# STM32U083 register map
File version: 1.0
CPU: CM0+ r0p1, little endian, MPU, no FPU, 4 interrupt priority bits
Registers are 32-bit, read-write, reset 0x0 unless marked. A register's access mark holds for its fields unless they carry their own. Offsets are from the block's base; [hi:lo] are bit positions.

## LPUART1 — LPUART address block description
Base 0x40008000
Same registers: LPUART2 0x40008400, LPUART3 0x40008C00
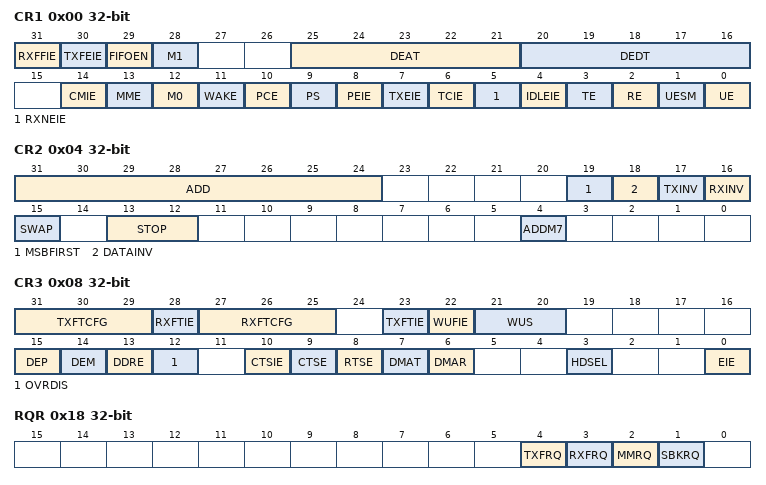
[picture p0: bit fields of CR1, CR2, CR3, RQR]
0x00 CR1 — LPUART control register 1
  [31] RXFFIE — RXFIFO Full interrupt enable This bit is set and cleared by software.
    0=Disabled (Interrupt inhibited); 1=Enabled (USART interrupt generated when RXFF = 1 in the USART_ISR register)
  [30] TXFEIE — TXFIFO empty interrupt enable This bit is set and cleared by software.
    0=Disabled (Interrupt inhibited); 1=Enabled (USART interrupt generated when TXFE = 1 in the USART_ISR register)
  [29] FIFOEN — FIFO mode enable This bit is set and cleared by software.
    0=Disabled (FIFO mode is disabled); 1=Enabled (FIFO mode is enabled)
  [28] M1 — Word length This bit must be used in conjunction with bit 12 (M0) to determine the word length. It is set or cleared by software. M[1:0] = 00: 1 Start bit, 8 Data bits, n Stop bit M[1:0] = 01: 1 Start bit, 9 Data bits, n Stop bit M[1:0] = 10: 1 Start bit, 7 Data bits, n Stop bit This bit can only be written when the LPUART is disabled (UE=0). Note: In 7-bit data length mode, the Smartcard mode, LIN master mode and auto baud rate (0x7F and 0x55 frames detection) are not supported.
    0=M0 (Use M0 to set the data bits); 1=Bit7 (1 start bit, 7 data bits, n stop bits)
  [25:21] DEAT — Driver Enable assertion time This 5-bit value defines the time between the activation of the DE (Driver Enable) signal and the beginning of the start bit. It is expressed in lpuart_ker_ck clock cycles. For more details, refer Section131.5.21: RS232 Hardware flow control and RS485 Driver Enable. This bitfield can only be written when the LPUART is disabled (UE=0).
  [20:16] DEDT — Driver Enable deassertion time This 5-bit value defines the time between the end of the last stop bit, in a transmitted message, and the de-activation of the DE (Driver Enable) signal.It is expressed in lpuart_ker_ck clock cycles. For more details, refer Section132.4.14: RS232 Hardware flow control and RS485 Driver Enable. If the LPUART_TDR register is written during the DEDT time, the new data is transmitted only when the DEDT and DEAT times have both elapsed. This bitfield can only be written when the LPUART is disabled (UE=0).
  [14] CMIE — Character match interrupt enable This bit is set and cleared by software.
    0=Disabled (Interrupt is disabled); 1=Enabled (Interrupt is generated when the CMF bit is set in the ISR register)
  [13] MME — Mute mode enable This bit activates the Mute mode function of the LPUART. When set, the LPUART can switch between the active and Mute modes, as defined by the WAKE bit. It is set and cleared by software.
    0=Disabled (Receiver in active mode permanently); 1=Enabled (Receiver can switch between mute mode and active mode)
  [12] M0 — Word length This bit is used in conjunction with bit 28 (M1) to determine the word length. It is set or cleared by software (refer to bit 28 (M1) description). This bit can only be written when the LPUART is disabled (UE=0).
    0=Bit8 (1 start bit, 8 data bits, n stop bits); 1=Bit9 (1 start bit, 9 data bits, n stop bits)
  [11] WAKE — Receiver wake-up method This bit determines the LPUART wake-up method from Mute mode. It is set or cleared by software. This bitfield can only be written when the LPUART is disabled (UE=0).
    0=Idle line; 1=Address mask
  [10] PCE — Parity control enable This bit selects the hardware parity control (generation and detection). When the parity control is enabled, the computed parity is inserted at the MSB position (9th bit if M=1; 8th bit if M=0) and parity is checked on the received data. This bit is set and cleared by software. Once it is set, PCE is active after the current byte (in reception and in transmission). This bitfield can only be written when the LPUART is disabled (UE=0).
    0=Disabled (Parity control disabled); 1=Enabled (Parity control enabled)
  [9] PS — Parity selection This bit selects the odd or even parity when the parity generation/detection is enabled (PCE bit set). It is set and cleared by software. The parity is selected after the current byte. This bitfield can only be written when the LPUART is disabled (UE=0).
    0=Even parity; 1=Odd (Odd parity)
  [8] PEIE — PE interrupt enable This bit is set and cleared by software.
    0=Disabled (Interrupt is disabled); 1=Enabled (Interrupt is generated whenever PE=1 in the ISR register)
  [7] TXEIE — TXFIFO not full interrupt enable This bit is set and cleared by software.
    0=Disabled (Interrupt is disabled); 1=Enabled (Interrupt is generated whenever TXE=1 in the ISR register)
  [6] TCIE — Transmission complete interrupt enable This bit is set and cleared by software.
    0=Disabled (Interrupt is disabled); 1=Enabled (Interrupt is generated whenever TC=1 in the ISR register)
  [5] RXNEIE — RXFIFO not empty interrupt enable This bit is set and cleared by software.
    0=Disabled (Interrupt is disabled); 1=Enabled (Interrupt is generated whenever ORE=1 or RXNE=1 in the ISR register)
  [4] IDLEIE — IDLE interrupt enable This bit is set and cleared by software.
    0=Disabled (Interrupt is disabled); 1=Enabled (Interrupt is generated whenever IDLE=1 in the ISR register)
  [3] TE — Transmitter enable This bit enables the transmitter. It is set and cleared by software. Note: During transmission, a low pulse on the TE bit (0 followed by 1) sends a preamble (idle line) after the current word, except in Smartcard mode. In order to generate an idle character, the TE must not be immediately written to 1. To ensure the required duration, the software can poll the TEACK bit in the LPUART_ISR register. Note: In Smartcard mode, when TE is set, there is a 1 bit-time delay before the transmission starts.
    0=Disabled (Transmitter is disabled); 1=Enabled (Transmitter is enabled)
  [2] RE — Receiver enable This bit enables the receiver. It is set and cleared by software.
    0=Disabled (Receiver is disabled); 1=Enabled (Receiver is enabled)
  [1] UESM — LPUART enable in low-power mode When this bit is cleared, the LPUART cannot wake up the MCU from low-power mode. When this bit is set, the LPUART can wake up the MCU from low-power mode. This bit is set and cleared by software. Note: It is recommended to set the UESM bit just before entering low-power mode, and clear it when exiting low-power mode.
    0=Disabled (USART not able to wake up the MCU from Stop mode); 1=Enabled (USART able to wake up the MCU from Stop mode)
  [0] UE — LPUART enable When this bit is cleared, the LPUART prescalers and outputs are stopped immediately, and current operations are discarded. The configuration of the LPUART is kept, but all the status flags, in the LPUART_ISR are reset. This bit is set and cleared by software. Note: To enter low-power mode without generating errors on the line, the TE bit must be reset before and the software must wait for the TC bit in the LPUART_ISR to be set before resetting the UE bit. Note: The DMA requests are also reset when UE = 0 so the DMA channel must be disabled before resetting the UE bit.
    0=Disabled (UART is disabled); 1=Enabled (UART is enabled)
0x04 CR2 — LPUART control register 2
  [31:24] ADD — Address of the LPUART node These bits give the address of the LPUART node in Mute mode or a character code to be recognized in low-power or Run mode: In Mute mode: they are used in multiprocessor communication to wake up from Mute mode with 4-bit/7-bit address mark detection. The MSB of the character sent by the transmitter should be equal to 1. In 4-bit address mark detection, only ADD[3:0] bits are used. In low-power mode: they are used for wake up from low-power mode on character match. When WUS[1:0] is programmed to 0b00 (WUF active on address match), the wake-up from low-power mode is performed when the received character corresponds to the character programmed through ADD[6:0] or ADD[3:0] bitfield (depending on ADDM7 bit), and WUF interrupt is enabled by setting WUFIE bit. The MSB of the character sent by transmitter should be equal to 1. In Run mode with Mute mode inactive (for example, end-of-block detection in ModBus protocol): the whole received character (8 bits) is compared to ADD[7:0] value and CMF flag is set on match. An interrupt is generated if the CMIE bit is set. These bits can only be written when the reception is disabled (RE1=10) or when the USART is disabled (UE1=10).
  [19] MSBFIRST — Most significant bit first This bit is set and cleared by software. This bitfield can only be written when the LPUART is disabled (UE=0).
    0=LSB (data is transmitted/received with data bit 0 first, following the start bit); 1=MSB (data is transmitted/received with MSB (bit 7/8/9) first, following the start bit)
  [18] DATAINV — Binary data inversion This bit is set and cleared by software. This bitfield can only be written when the LPUART is disabled (UE=0).
    0=Positive (Logical data from the data register are send/received in positive/direct logic); 1=Negative (Logical data from the data register are send/received in negative/inverse logic)
  [17] TXINV — TX pin active level inversion This bit is set and cleared by software. This enables the use of an external inverter on the TX line. This bitfield can only be written when the LPUART is disabled (UE=0).
    0=Standard (TX pin signal works using the standard logic levels); 1=Inverted (TX pin signal values are inverted)
  [16] RXINV — RX pin active level inversion This bit is set and cleared by software. This enables the use of an external inverter on the RX line. This bitfield can only be written when the LPUART is disabled (UE=0).
    0=Standard (RX pin signal works using the standard logic levels); 1=Inverted (RX pin signal values are inverted)
  [15] SWAP — Swap TX/RX pins This bit is set and cleared by software. This bitfield can only be written when the LPUART is disabled (UE=0).
    0=Standard (TX/RX pins are used as defined in standard pinout); 1=Swapped (The TX and RX pins functions are swapped)
  [13:12] STOP — STOP bits These bits are used for programming the stop bits. This bitfield can only be written when the LPUART is disabled (UE=0).
    0=1 stop bit; 2=2 stop bit
  [4] ADDM7 — 7-bit Address Detection/4-bit Address Detection This bit is for selection between 4-bit address detection or 7-bit address detection. This bit can only be written when the LPUART is disabled (UE=0) Note: In 7-bit and 9-bit data modes, the address detection is done on 6-bit and 8-bit address (ADD[5:0] and ADD[7:0]) respectively.
    0=Bit4 (4-bit address detection); 1=Bit7 (7-bit address detection)
0x08 CR3 access not given — LPUART control register 3
  [31:29] TXFTCFG rw — TXFIFO threshold configuration Remaining combinations: Reserved.
    0=Depth_1_8 (TXFIFO reaches 1/8 of its depth); 1=Depth_1_4 (TXFIFO reaches 1/4 of its depth); 2=Depth_1_2 (TXFIFO reaches 1/2 of its depth); 3=Depth_3_4 (TXFIFO reaches 3/4 of its depth); 4=Depth_7_8 (TXFIFO reaches 7/8 of its depth); 5=Empty (TXFIFO becomes empty)
  [28] RXFTIE rw — RXFIFO threshold interrupt enable This bit is set and cleared by software.
    0=Disabled (Interrupt inhibited); 1=Enabled (USART interrupt generated when Receive FIFO reaches the threshold programmed in RXFTCFG)
  [27:25] RXFTCFG rw — Receive FIFO threshold configuration Remaining combinations: Reserved.
    0=Depth_1_8 (RXFIFO reaches 1/8 of its depth); 1=Depth_1_4 (RXFIFO reaches 1/4 of its depth); 2=Depth_1_2 (RXFIFO reaches 1/2 of its depth); 3=Depth_3_4 (RXFIFO reaches 3/4 of its depth); 4=Depth_7_8 (RXFIFO reaches 7/8 of its depth); 5=Full (RXFIFO becomes full)
  [23] TXFTIE rw — TXFIFO threshold interrupt enable This bit is set and cleared by software.
    0=Disabled (Interrupt inhibited); 1=Enabled (USART interrupt generated when Transmit FIFO reaches the threshold programmed in TXFTCFG)
  [22] WUFIE rw — Wake-up from low-power mode interrupt enable This bit is set and cleared by software. Note: WUFIE must be set before entering in low-power mode. Note: If the USART does not support the wake-up from Stop feature, this bit is reserved and must be kept at reset value. Refer to Section132.3: LPUART implementation on page1914.
    0=Disabled (Interrupt is inhibited); 1=Enabled (An USART interrupt is generated whenever WUF=1 in the ISR register)
  [21:20] WUS — Wake-up from low-power mode interrupt flag selection This bitfield specifies the event which activates the WUF (Wake-up from low-power mode flag). This bitfield can only be written when the LPUART is disabled (UE=0). Note: If the USART does not support the wake-up from Stop feature, this bit is reserved and must be kept at reset value. Refer to Section132.3: LPUART implementation on page1914.
    0=Address (WUF active on address match); 2=Start (WuF active on Start bit detection); 3=RXNE (WUF active on RXNE)
  [15] DEP rw — Driver enable polarity selection This bit can only be written when the LPUART is disabled (UE=0).
    0=High (DE signal is active high); 1=Low (DE signal is active low)
  [14] DEM rw — Driver enable mode This bit enables the user to activate the external transceiver control, through the DE signal. This bit can only be written when the LPUART is disabled (UE=0).
    0=Disabled (DE function is disabled); 1=Enabled (The DE signal is output on the RTS pin)
  [13] DDRE rw — DMA Disable on Reception Error This bit can only be written when the LPUART is disabled (UE=0). Note: The reception errors are: parity error, framing error or noise error.
    0=NotDisabled (DMA is not disabled in case of reception error); 1=Disabled (DMA is disabled following a reception error)
  [12] OVRDIS rw — Overrun Disable This bit is used to disable the receive overrun detection. the ORE flag is not set and the new received data overwrites the previous content of the LPUART_RDR register. This bit can only be written when the LPUART is disabled (UE=0). Note: This control bit enables checking the communication flow w/o reading the data.
    0=Enabled (Overrun Error Flag, ORE, is set when received data is not read before receiving new data); 1=Disabled (Overrun functionality is disabled. If new data is received while the RXNE flag is still set the ORE flag is not set and the new received data overwrites the previous content of the RDR register)
  [10] CTSIE rw — CTS interrupt enable
    0=Disabled (Interrupt is inhibited); 1=Enabled (An interrupt is generated whenever CTSIF=1 in the ISR register)
  [9] CTSE rw — CTS enable This bit can only be written when the LPUART is disabled (UE=0)
    0=Disabled (CTS hardware flow control disabled); 1=Enabled (CTS mode enabled, data is only transmitted when the CTS input is asserted)
  [8] RTSE rw — RTS enable This bit can only be written when the LPUART is disabled (UE=0).
    0=Disabled (RTS hardware flow control disabled); 1=Enabled (RTS output enabled, data is only requested when there is space in the receive buffer)
  [7] DMAT rw — DMA enable transmitter This bit is set/reset by software
    0=Disabled (DMA mode is disabled for transmission); 1=Enabled (DMA mode is enabled for transmission)
  [6] DMAR rw — DMA enable receiver This bit is set/reset by software
    0=Disabled (DMA mode is disabled for reception); 1=Enabled (DMA mode is enabled for reception)
  [3] HDSEL rw — Half-duplex selection Selection of Single-wire Half-duplex mode This bit can only be written when the LPUART is disabled (UE=0).
    0=NotSelected (Half duplex mode is not selected); 1=Selected (Half duplex mode is selected)
  [0] EIE rw — Error interrupt enable Error Interrupt Enable Bit is required to enable interrupt generation in case of a framing error, overrun error or noise flag (FE=1 or ORE=1 or NE=1 in the LPUART_ISR register).
    0=Disabled (Interrupt is inhibited); 1=Enabled (An interrupt is generated when FE=1 or ORE=1 or NF=1 in the ISR register)
0x0C BRR — LPUART baud rate register
  [19:0] BRR — LPUART baud rate division (LPUARTDIV)
0x18 RQR wo — LPUART request register
  [4] TXFRQ — Transmit data flush request This bit is used when FIFO mode is enabled. TXFRQ bit is set to flush the whole FIFO. This sets the flag TXFE (TXFIFO empty, bit 23 in the LPUART_ISR register). Note: In FIFO mode, the TXFNF flag is reset during the flush request until TxFIFO is empty in order to ensure that no data are written in the data register.
    1=Discard (Set the TXE flags. This allows to discard the transmit data)
  [3] RXFRQ — Receive data flush request Writing 1 to this bit clears the RXNE flag. This enables discarding the received data without reading it, and avoid an overrun condition.
    1=Discard (clears the RXNE flag. This allows to discard the received data without reading it, and avoid an overrun condition)
  [2] MMRQ — Mute mode request Writing 1 to this bit puts the LPUART in Mute mode and resets the RWU flag.
    1=Mute (Puts the USART in mute mode and sets the RWU flag)
  [1] SBKRQ — Send break request Writing 1 to this bit sets the SBKF flag and request to send a BREAK on the line, as soon as the transmit machine is available. Note: If the application needs to send the break character following all previously inserted data, including the ones not yet transmitted, the software must wait for the TXE flag assertion before setting the SBKRQ bit.
    1=Break (sets the SBKF flag and request to send a BREAK on the line, as soon as the transmit machine is available)
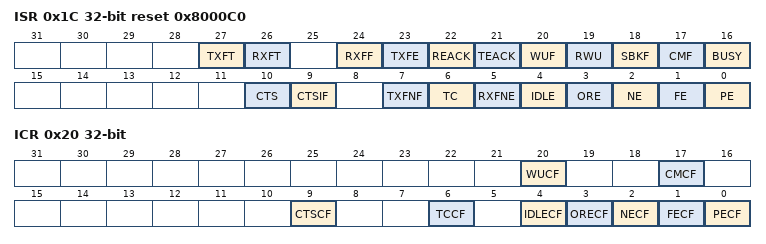
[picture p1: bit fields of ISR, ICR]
0x1C ISR ro reset 0x8000C0 — LPUART interrupt and status register
  [27] TXFT — TXFIFO threshold flag This bit is set by hardware when the TXFIFO reaches the threshold programmed in TXFTCFG in LPUART_CR3 register i.e. the TXFIFO contains TXFTCFG empty locations. An interrupt is generated if the TXFTIE bit =1 (bit 31) in the LPUART_CR3 register.
    0=NotReached (TXFIFO does not reach the programmed threshold.); 1=Reached (TXFIFO reached the programmed threshold.)
  [26] RXFT — RXFIFO threshold flag This bit is set by hardware when the RXFIFO reaches the threshold programmed in RXFTCFG in LPUART_CR3 register i.e. the Receive FIFO contains RXFTCFG data. An interrupt is generated if the RXFTIE bit =1 (bit 27) in the LPUART_CR3 register.
    0=NotReached (Receive FIFO does not reach the programmed threshold.); 1=Reached (Receive FIFO reached the programmed threshold.)
  [24] RXFF — RXFIFO Full This bit is set by hardware when the number of received data corresponds to RXFIFO1size1+11 (RXFIFO full + 1 data in the LPUART_RDR register. An interrupt is generated if the RXFFIE bit =1 in the LPUART_CR1 register.
    0=NotFull (RXFIFO not full.); 1=Full (RXFIFO Full.)
  [23] TXFE — TXFIFO Empty This bit is set by hardware when TXFIFO is Empty. When the TXFIFO contains at least one data, this flag is cleared. The TXFE flag can also be set by writing 1 to the bit TXFRQ (bit 4) in the LPUART_RQR register. An interrupt is generated if the TXFEIE bit =1 (bit 30) in the LPUART_CR1 register.
    0=NotEmpty (TXFIFO not empty.); 1=Empty (TXFIFO empty.)
  [22] REACK — Receive enable acknowledge flag This bit is set/reset by hardware, when the Receive Enable value is taken into account by the LPUART. It can be used to verify that the LPUART is ready for reception before entering low-power mode. Note: If the LPUART does not support the wake-up from Stop feature, this bit is reserved and kept at reset value.
  [21] TEACK — Transmit enable acknowledge flag This bit is set/reset by hardware, when the Transmit Enable value is taken into account by the LPUART. It can be used when an idle frame request is generated by writing TE=0, followed by TE=1 in the LPUART_CR1 register, in order to respect the TE=0 minimum period.
  [20] WUF — Wake-up from low-power mode flag This bit is set by hardware, when a wake-up event is detected. The event is defined by the WUS bitfield. It is cleared by software, writing a 1 to the WUCF in the LPUART_ICR register. An interrupt is generated if WUFIE=1 in the LPUART_CR3 register. Note: When UESM is cleared, WUF flag is also cleared. Note: If the USART does not support the wake-up from Stop feature, this bit is reserved and kept at reset value. Refer to Section132.3: LPUART implementation on page1914.
  [19] RWU — Receiver wake-up from Mute mode This bit indicates if the LPUART is in Mute mode. It is cleared/set by hardware when a wake-up/mute sequence is recognized. The Mute mode control sequence (address or IDLE) is selected by the WAKE bit in the LPUART_CR1 register. When wake-up on IDLE mode is selected, this bit can only be set by software, writing 1 to the MMRQ bit in the LPUART_RQR register. Note: If the LPUART does not support the wake-up from Stop feature, this bit is reserved and kept at reset value.
    0=Active (Receiver in Active mode); 1=Mute (Receiver in Mute mode)
  [18] SBKF — Send break flag This bit indicates that a send break character was requested. It is set by software, by writing 1 to the SBKRQ bit in the LPUART_CR3 register. It is automatically reset by hardware during the stop bit of break transmission.
    0=No break character transmitted; 1=Break character transmitted
  [17] CMF — Character match flag This bit is set by hardware, when a the character defined by ADD[7:0] is received. It is cleared by software, writing 1 to the CMCF in the LPUART_ICR register. An interrupt is generated if CMIE=1in the LPUART_CR1 register.
    0=NoMatch (No Character match detected); 1=Match (Character match detected)
  [16] BUSY — Busy flag This bit is set and reset by hardware. It is active when a communication is ongoing on the RX line (successful start bit detected). It is reset at the end of the reception (successful or not).
    0=Idle (USART is idle (no reception)); 1=Busy (Reception on going)
  [10] CTS — CTS flag This bit is set/reset by hardware. It is an inverted copy of the status of the CTS input pin. Note: If the hardware flow control feature is not supported, this bit is reserved and kept at reset value.
    0=Set (CTS line set); 1=Reset (CTS line reset)
  [9] CTSIF — CTS interrupt flag This bit is set by hardware when the CTS input toggles, if the CTSE bit is set. It is cleared by software, by writing 1 to the CTSCF bit in the LPUART_ICR register. An interrupt is generated if CTSIE=1 in the LPUART_CR3 register. Note: If the hardware flow control feature is not supported, this bit is reserved and kept at reset value.
    0=NotChanged (No change occurred on the CTS status line); 1=Changed (A change occurred on the CTS status line)
  [7] TXFNF — TXFIFO not full TXFNF is set by hardware when TXFIFO is not full, and so data can be written in the LPUART_TDR. Every write in the LPUART_TDR places the data in the TXFIFO. This flag remains set until the TXFIFO is full. When the TXFIFO is full, this flag is cleared indicating that data can not be written into the LPUART_TDR. The TXFNF is kept reset during the flush request until TXFIFO is empty. After sending the flush request (by setting TXFRQ bit), the flag TXFNF must be checked prior to writing in TXFIFO (TXFNF and TXFE are set at the same time). An interrupt is generated if the TXFNFIE bit =1 in the LPUART_CR1 register. Note: This bit is used during single buffer transmission.
    0=Full (Transmit FIFO is full); 1=NotFull (Transmit FIFO is not full)
  [6] TC — Transmission complete This bit indicates that the last data written in the LPUART_TDR has been transmitted out of the shift register. The TC flag behaves as follows: When TDN = 0, the TC flag is set when the transmission of a frame containing data is complete and when TXFE is set. When TDN is equal to the number of data in the TXFIFO, the TC flag is set when TXFIFO is empty and TDN is reached. When TDN is greater than the number of data in the TXFIFO, TC remains cleared until the TXFIFO is filled again to reach the programmed number of data to be transferred. When TDN is less than the number of data in the TXFIFO, TC is set when TDN is reached even if the TXFIFO is not empty. An interrupt is generated if TCIE=1 in the LPUART_CR1 register. TC bit is cleared by software by writing 1 to the TCCF in the LPUART_ICR register or by writing to the LPUART_TDR register.
    0=TxNotComplete (Transmission is not complete); 1=TxComplete (Transmission is complete)
  [5] RXFNE — RXFIFO not empty RXFNE bit is set by hardware when the RXFIFO is not empty, and so data can be read from the LPUART_RDR register. Every read of the LPUART_RDR frees a location in the RXFIFO. It is cleared when the RXFIFO is empty. The RXFNE flag can also be cleared by writing 1 to the RXFRQ in the LPUART_RQR register. An interrupt is generated if RXFNEIE=1 in the LPUART_CR1 register.
    0=NoData (Data is not received); 1=DataReady (Received data is ready to be read)
  [4] IDLE — Idle line detected This bit is set by hardware when an Idle line is detected. An interrupt is generated if IDLEIE=1 in the LPUART_CR1 register. It is cleared by software, writing 1 to the IDLECF in the LPUART_ICR register. Note: The IDLE bit is not set again until the RXFNE bit has been set (i.e. a new idle line occurs). Note: If Mute mode is enabled (MME=1), IDLE is set if the LPUART is not mute (RWU=0), whatever the Mute mode selected by the WAKE bit. If RWU=1, IDLE is not set.
    0=No Idle Line is detected; 1=Idle Line is detected
  [3] ORE — Overrun error This bit is set by hardware when the data currently being received in the shift register is ready to be transferred into the LPUART_RDR register while RXFF = 1. It is cleared by a software, writing 1 to the ORECF, in the LPUART_ICR register. An interrupt is generated if RXFNEIE=1 in the LPUART_CR1 register, or EIE = 1 in the LPUART_CR3 register. Note: When this bit is set, the LPUART_RDR register content is not lost but the shift register is overwritten. An interrupt is generated if the ORE flag is set during multi buffer communication if the EIE bit is set. Note: This bit is permanently forced to 0 (no overrun detection) when the bit OVRDIS is set in the LPUART_CR3 register.
    0=No Overrun error; 1=Overrun error is detected
  [2] NE — Start bit noise detection flag This bit is set by hardware when noise is detected on the start bit of a received frame. It is cleared by software, writing 1 to the NFCF bit in the LPUART_ICR register. Note: This bit does not generate an interrupt as it appears at the same time as the RXFNE bit which itself generates an interrupt. An interrupt is generated when the NE flag is set during multi buffer communication if the EIE bit is set. Note: This error is associated with the character in the LPUART_RDR.
    0=No noise is detected; 1=Noise is detected
  [1] FE — Framing error This bit is set by hardware when a de-synchronization, excessive noise or a break character is detected. It is cleared by software, writing 1 to the FECF bit in the LPUART_ICR register. When transmitting data in Smartcard mode, this bit is set when the maximum number of transmit attempts is reached without success (the card NACKs the data frame). An interrupt is generated if EIE1=11 in the LPUART_CR3 register. Note: This error is associated with the character in the LPUART_RDR.
    0=NoError (No Framing error is detected); 1=Error (Framing error or break character is detected)
  [0] PE — Parity error This bit is set by hardware when a parity error occurs in Reception mode. It is cleared by software, writing 1 to the PECF in the LPUART_ICR register. An interrupt is generated if PEIE = 1 in the LPUART_CR1 register. Note: This error is associated with the character in the LPUART_RDR.
    0=NoError (No parity error); 1=Error (Parity error)
0x20 ICR wo — LPUART interrupt flag clear register
  [20] WUCF write-1-clears — Wake-up from low-power mode clear flag Writing 1 to this bit clears the WUF flag in the USART_ISR register. Note: If the USART does not support the wake-up from Stop feature, this bit is reserved and must be kept at reset value. Refer to Section132.3: LPUART implementation on page1914.
    1=Clears the WUF flag in the ISR register
  [17] CMCF write-1-clears — Character match clear flag Writing 1 to this bit clears the CMF flag in the LPUART_ISR register.
    1=Clears the CMF flag in the ISR register
  [9] CTSCF write-1-clears — CTS clear flag Writing 1 to this bit clears the CTSIF flag in the LPUART_ISR register.
    1=Clears the CTSIF flag in the ISR register
  [6] TCCF write-1-clears — Transmission complete clear flag Writing 1 to this bit clears the TC flag in the LPUART_ISR register.
    1=Clears the TC flag in the ISR register
  [4] IDLECF write-1-clears — Idle line detected clear flag Writing 1 to this bit clears the IDLE flag in the LPUART_ISR register.
    1=Clears the IDLE flag in the ISR register
  [3] ORECF write-1-clears — Overrun error clear flag Writing 1 to this bit clears the ORE flag in the LPUART_ISR register.
    1=Clears the ORE flag in the ISR register
  [2] NECF write-1-clears — Noise detected clear flag Writing 1 to this bit clears the NE flag in the LPUART_ISR register.
    1=Clears the NF flag in the ISR register
  [1] FECF write-1-clears — Framing error clear flag Writing 1 to this bit clears the FE flag in the LPUART_ISR register.
    1=Clears the FE flag in the ISR register
  [0] PECF write-1-clears — Parity error clear flag Writing 1 to this bit clears the PE flag in the LPUART_ISR register.
    1=Clears the PE flag in the ISR register
0x24 RDR ro — LPUART receive data register
  [8:0] RDR — Receive data value Contains the received data character. The RDR register provides the parallel interface between the input shift register and the internal bus (see Figure1254). When receiving with the parity enabled, the value read in the MSB bit is the received parity bit.
0x28 TDR — LPUART transmit data register
  [8:0] TDR — Transmit data value Contains the data character to be transmitted. The TDR register provides the parallel interface between the internal bus and the output shift register (see Figure1254). When transmitting with the parity enabled (PCE bit set to 1 in the LPUART_CR1 register), the value written in the MSB (bit 7 or bit 8 depending on the data length) has no effect because it is replaced by the parity. Note: This register must be written only when TXE/TXFNF=1.
0x2C PRESC — LPUART prescaler register
  [3:0] PRESCALER — Clock prescaler The LPUART input clock can be divided by a prescaler: Remaining combinations: Reserved. Note: When PRESCALER is programmed with a value different of the allowed ones, programmed prescaler value is equal to 1011 i.e. input clock divided by 256.
    0=Div1 (/1); 1=Div2 (/2); 2=Div4 (/4); 3=Div6 (/6); 4=Div8 (/8); 5=Div10 (/10); 6=Div12 (/12); 7=Div16 (/16); 8=Div32 (/32); 9=Div64 (/64); 10=Div128 (/128); 11=Div256 (/256)
